AUTOSAR XML (schema 4-3-0)
standard types defined: uint8
package /Acme/Chassis/DataTypes
  impl type WheelSpeedValue_impl: category=VALUE, base-type=uint8  # Implementation type for a raw wheel speed sample (anonymized fixture).
package /Acme/Chassis/Interfaces
  sender receiver interface IWheelSpeed  # Wheel speed sender/receiver interface (anonymized fixture).
    data speedValue: type=WheelSpeedValue_impl  # Current wheel speed value.
package /Acme/Chassis/Components
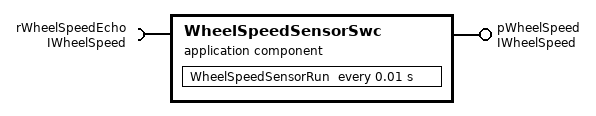
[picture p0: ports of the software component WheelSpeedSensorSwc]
  application sw component type WheelSpeedSensorSwc  # Wheel speed sensor application component (anonymized fixture).
    provide port pWheelSpeed: provided-interface=IWheelSpeed  # Provides the current wheel speed reading.
    require port rWheelSpeedEcho: required-interface=IWheelSpeed  # Requires a loop-back echo of the wheel speed value.
    behavior WheelSpeedSensorSwc_InternalBehavior: port-api-option{enable-take-address=false, indirect-api=false, port=pWheelSpeed}
      timing event TMT_WheelSpeedSensorRun: start-on-event=WheelSpeedSensorRun, period=0.01
      runnable WheelSpeedSensorRun: minimum-start-interval=0.01
  swc implementation WheelSpeedSensorSwc_Implementation: behavior=WheelSpeedSensorSwc_InternalBehavior
